AUTOSAR XML (schema 00046)
package /ComponentTypes
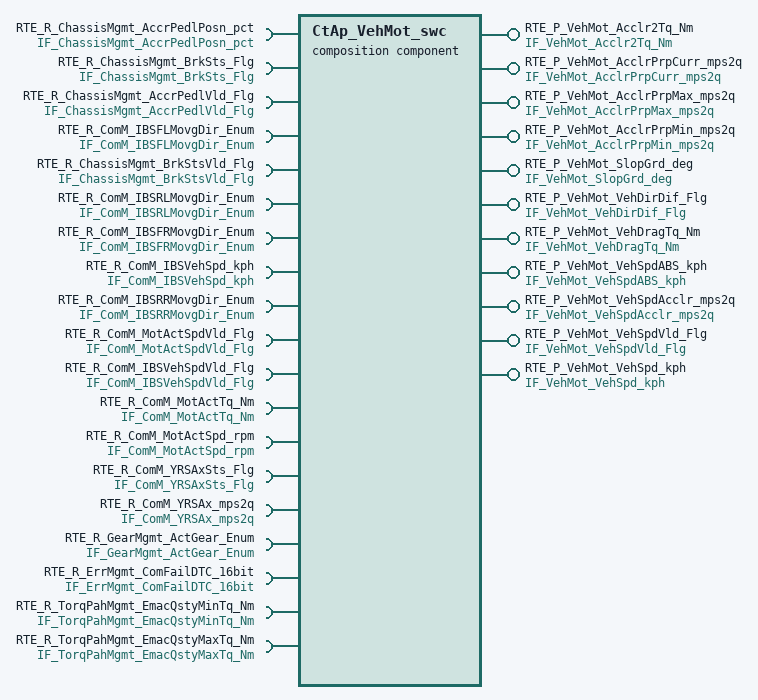
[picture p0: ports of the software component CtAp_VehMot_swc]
  composition sw component type CtAp_VehMot_swc
    11 x provide port:
      RTE_P_VehMot_Acclr2Tq_Nm: nonqueued-sender-com-spec{data-element=tec_VehMot_Acclr2Tq_Nm, init-value=0}, provided-interface=IF_VehMot_Acclr2Tq_Nm
      RTE_P_VehMot_AcclrPrpCurr_mps2q: nonqueued-sender-com-spec{data-element=tec_VehMot_AcclrPrpCurr_mps2q, init-value=0}, provided-interface=IF_VehMot_AcclrPrpCurr_mps2q
      RTE_P_VehMot_AcclrPrpMax_mps2q: nonqueued-sender-com-spec{data-element=tec_VehMot_AcclrPrpMax_mps2q, init-value=0}, provided-interface=IF_VehMot_AcclrPrpMax_mps2q
      RTE_P_VehMot_AcclrPrpMin_mps2q: nonqueued-sender-com-spec{data-element=tec_VehMot_AcclrPrpMin_mps2q, init-value=0}, provided-interface=IF_VehMot_AcclrPrpMin_mps2q
      RTE_P_VehMot_SlopGrd_deg: nonqueued-sender-com-spec{data-element=tec_VehMot_SlopGrd_deg, init-value=0}, provided-interface=IF_VehMot_SlopGrd_deg
      RTE_P_VehMot_VehDirDif_Flg: nonqueued-sender-com-spec{data-element=tec_VehMot_VehDirDif_Flg, init-value=0}, provided-interface=IF_VehMot_VehDirDif_Flg
      RTE_P_VehMot_VehDragTq_Nm: nonqueued-sender-com-spec{data-element=tec_VehMot_VehDragTq_Nm, init-value=0}, provided-interface=IF_VehMot_VehDragTq_Nm
      RTE_P_VehMot_VehSpdABS_kph: nonqueued-sender-com-spec{data-element=tec_VehMot_VehSpdABS_kph, init-value=0}, provided-interface=IF_VehMot_VehSpdABS_kph
      RTE_P_VehMot_VehSpdAcclr_mps2q: nonqueued-sender-com-spec{data-element=tec_VehMot_VehSpdAcclr_mps2q, init-value=0}, provided-interface=IF_VehMot_VehSpdAcclr_mps2q
      RTE_P_VehMot_VehSpdVld_Flg: nonqueued-sender-com-spec{data-element=tec_VehMot_VehSpdVld_Flg, init-value=0}, provided-interface=IF_VehMot_VehSpdVld_Flg
      RTE_P_VehMot_VehSpd_kph: nonqueued-sender-com-spec{data-element=tec_VehMot_VehSpd_kph, init-value=0}, provided-interface=IF_VehMot_VehSpd_kph
    19 x require port:
      RTE_R_ChassisMgmt_AccrPedlPosn_pct: nonqueued-receiver-com-spec{data-element=tec_ChassisMgmt_AccrPedlPosn_pct, filter=data-filter-type=ALWAYS, init-value=0}, required-interface=IF_ChassisMgmt_AccrPedlPosn_pct
      RTE_R_ChassisMgmt_BrkSts_Flg: nonqueued-receiver-com-spec{data-element=tec_ChassisMgmt_BrkSts_Flg, filter=data-filter-type=ALWAYS, init-value=0}, required-interface=IF_ChassisMgmt_BrkSts_Flg
      RTE_R_ChassisMgmt_AccrPedlVld_Flg: nonqueued-receiver-com-spec{data-element=tec_ChassisMgmt_AccrPedlVld_Flg, filter=data-filter-type=ALWAYS, init-value=0}, required-interface=IF_ChassisMgmt_AccrPedlVld_Flg
      RTE_R_ComM_IBSFLMovgDir_Enum: nonqueued-receiver-com-spec{data-element=tec_ComM_IBSFLMovgDir_Enum, filter=data-filter-type=ALWAYS, init-value=0}, required-interface=IF_ComM_IBSFLMovgDir_Enum
      RTE_R_ChassisMgmt_BrkStsVld_Flg: nonqueued-receiver-com-spec{data-element=tec_ChassisMgmt_BrkStsVld_Flg, filter=data-filter-type=ALWAYS, init-value=0}, required-interface=IF_ChassisMgmt_BrkStsVld_Flg
      RTE_R_ComM_IBSRLMovgDir_Enum: nonqueued-receiver-com-spec{data-element=tec_ComM_IBSRLMovgDir_Enum, filter=data-filter-type=ALWAYS, init-value=0}, required-interface=IF_ComM_IBSRLMovgDir_Enum
      RTE_R_ComM_IBSFRMovgDir_Enum: nonqueued-receiver-com-spec{data-element=tec_ComM_IBSFRMovgDir_Enum, filter=data-filter-type=ALWAYS, init-value=0}, required-interface=IF_ComM_IBSFRMovgDir_Enum
      RTE_R_ComM_IBSVehSpd_kph: nonqueued-receiver-com-spec{data-element=tec_ComM_IBSVehSpd_kph, filter=data-filter-type=ALWAYS, init-value=0}, required-interface=IF_ComM_IBSVehSpd_kph
      RTE_R_ComM_IBSRRMovgDir_Enum: nonqueued-receiver-com-spec{data-element=tec_ComM_IBSRRMovgDir_Enum, filter=data-filter-type=ALWAYS, init-value=0}, required-interface=IF_ComM_IBSRRMovgDir_Enum
      RTE_R_ComM_MotActSpdVld_Flg: nonqueued-receiver-com-spec{data-element=tec_ComM_MotActSpdVld_Flg, filter=data-filter-type=ALWAYS, init-value=0}, required-interface=IF_ComM_MotActSpdVld_Flg
      RTE_R_ComM_IBSVehSpdVld_Flg: nonqueued-receiver-com-spec{data-element=tec_ComM_IBSVehSpdVld_Flg, filter=data-filter-type=ALWAYS, init-value=0}, required-interface=IF_ComM_IBSVehSpdVld_Flg
      RTE_R_ComM_MotActTq_Nm: nonqueued-receiver-com-spec{data-element=tec_ComM_MotActTq_Nm, filter=data-filter-type=ALWAYS, init-value=0}, required-interface=IF_ComM_MotActTq_Nm
      RTE_R_ComM_MotActSpd_rpm: nonqueued-receiver-com-spec{data-element=tec_ComM_MotActSpd_rpm, filter=data-filter-type=ALWAYS, init-value=0}, required-interface=IF_ComM_MotActSpd_rpm
      RTE_R_ComM_YRSAxSts_Flg: nonqueued-receiver-com-spec{data-element=tec_ComM_YRSAxSts_Flg, filter=data-filter-type=ALWAYS, init-value=0}, required-interface=IF_ComM_YRSAxSts_Flg
      RTE_R_ComM_YRSAx_mps2q: nonqueued-receiver-com-spec{data-element=tec_ComM_YRSAx_mps2q, filter=data-filter-type=ALWAYS, init-value=0}, required-interface=IF_ComM_YRSAx_mps2q
      RTE_R_GearMgmt_ActGear_Enum: nonqueued-receiver-com-spec{data-element=tec_GearMgmt_ActGear_Enum, filter=data-filter-type=ALWAYS, init-value=0}, required-interface=IF_GearMgmt_ActGear_Enum
      RTE_R_ErrMgmt_ComFailDTC_16bit: nonqueued-receiver-com-spec{data-element=tec_ErrMgmt_ComFailDTC_16bit, filter=data-filter-type=ALWAYS, init-value=0}, required-interface=IF_ErrMgmt_ComFailDTC_16bit
      RTE_R_TorqPahMgmt_EmacQstyMinTq_Nm: nonqueued-receiver-com-spec{data-element=tec_TorqPahMgmt_EmacQstyMinTq_Nm, filter=data-filter-type=ALWAYS, init-value=0}, required-interface=IF_TorqPahMgmt_EmacQstyMinTq_Nm
      RTE_R_TorqPahMgmt_EmacQstyMaxTq_Nm: nonqueued-receiver-com-spec{data-element=tec_TorqPahMgmt_EmacQstyMaxTq_Nm, filter=data-filter-type=ALWAYS, init-value=0}, required-interface=IF_TorqPahMgmt_EmacQstyMaxTq_Nm
    4 x component:
      CtAp_VehSpd: type=CtAp_VehSpd
      CtAp_AccCal: type=CtAp_AccCal
      CtAp_SlopEst: type=CtAp_SlopEst
      CtAp_ResEst: type=CtAp_ResEst
    connect CtAp_VehSpd.RTE_P_VehMot_VehSpd_kph -> CtAp_ResEst.RTE_R_VehMot_VehSpd_kph
    connect CtAp_AccCal.RTE_P_VehMot_VehSpdAcclr_mps2q -> CtAp_ResEst.RTE_R_VehMot_VehSpdAcclr_mps2q
    connect CtAp_VehSpd.RTE_P_VehMot_VehSpdVld_Flg -> CtAp_ResEst.RTE_R_VehMot_VehSpdVld_Flg
    connect CtAp_VehSpd.RTE_P_VehMot_VehSpd_kph -> CtAp_SlopEst.RTE_R_VehMot_VehSpd_kph
    connect CtAp_AccCal.RTE_P_VehMot_VehSpdAcclr_mps2q -> CtAp_SlopEst.RTE_R_VehMot_VehSpdAcclr_mps2q
    delegate CtAp_ResEst.RTE_P_VehMot_Acclr2Tq_Nm <-> outer port RTE_P_VehMot_Acclr2Tq_Nm
    delegate CtAp_ResEst.RTE_P_VehMot_AcclrPrpCurr_mps2q <-> outer port RTE_P_VehMot_AcclrPrpCurr_mps2q
    delegate CtAp_ResEst.RTE_P_VehMot_AcclrPrpMax_mps2q <-> outer port RTE_P_VehMot_AcclrPrpMax_mps2q
    delegate CtAp_ResEst.RTE_P_VehMot_AcclrPrpMin_mps2q <-> outer port RTE_P_VehMot_AcclrPrpMin_mps2q
    delegate CtAp_SlopEst.RTE_P_VehMot_SlopGrd_deg <-> outer port RTE_P_VehMot_SlopGrd_deg
    delegate CtAp_VehSpd.RTE_P_VehMot_VehDirDif_Flg <-> outer port RTE_P_VehMot_VehDirDif_Flg
    delegate CtAp_ResEst.RTE_P_VehMot_VehDragTq_Nm <-> outer port RTE_P_VehMot_VehDragTq_Nm
    delegate CtAp_VehSpd.RTE_P_VehMot_VehSpd_kph <-> outer port RTE_P_VehMot_VehSpd_kph
    delegate CtAp_VehSpd.RTE_P_VehMot_VehSpdABS_kph <-> outer port RTE_P_VehMot_VehSpdABS_kph
    delegate CtAp_AccCal.RTE_P_VehMot_VehSpdAcclr_mps2q <-> outer port RTE_P_VehMot_VehSpdAcclr_mps2q
    delegate CtAp_VehSpd.RTE_P_VehMot_VehSpdVld_Flg <-> outer port RTE_P_VehMot_VehSpdVld_Flg
    delegate CtAp_AccCal.RTE_R_ComM_YRSAx_mps2q <-> outer port RTE_R_ComM_YRSAx_mps2q
    delegate CtAp_AccCal.RTE_R_ComM_YRSAxSts_Flg <-> outer port RTE_R_ComM_YRSAxSts_Flg
    connect CtAp_VehSpd.RTE_P_VehMot_VehSpd_kph -> CtAp_AccCal.RTE_R_VehMot_VehSpd_kph
    delegate CtAp_ResEst.RTE_R_ChassisMgmt_BrkSts_Flg <-> outer port RTE_R_ChassisMgmt_BrkSts_Flg
    delegate CtAp_ResEst.RTE_R_ChassisMgmt_BrkStsVld_Flg <-> outer port RTE_R_ChassisMgmt_BrkStsVld_Flg
    delegate CtAp_ResEst.RTE_R_ComM_MotActTq_Nm <-> outer port RTE_R_ComM_MotActTq_Nm
    delegate CtAp_ResEst.RTE_R_ComM_YRSAx_mps2q <-> outer port RTE_R_ComM_YRSAx_mps2q
    delegate CtAp_ResEst.RTE_R_ComM_YRSAxSts_Flg <-> outer port RTE_R_ComM_YRSAxSts_Flg
    delegate CtAp_ResEst.RTE_R_TorqPahMgmt_EmacQstyMaxTq_Nm <-> outer port RTE_R_TorqPahMgmt_EmacQstyMaxTq_Nm
    delegate CtAp_ResEst.RTE_R_TorqPahMgmt_EmacQstyMinTq_Nm <-> outer port RTE_R_TorqPahMgmt_EmacQstyMinTq_Nm
    delegate CtAp_SlopEst.RTE_R_ChassisMgmt_AccrPedlPosn_pct <-> outer port RTE_R_ChassisMgmt_AccrPedlPosn_pct
    delegate CtAp_SlopEst.RTE_R_ChassisMgmt_AccrPedlVld_Flg <-> outer port RTE_R_ChassisMgmt_AccrPedlVld_Flg
    delegate CtAp_SlopEst.RTE_R_ChassisMgmt_BrkSts_Flg <-> outer port RTE_R_ChassisMgmt_BrkSts_Flg
    delegate CtAp_SlopEst.RTE_R_ChassisMgmt_BrkStsVld_Flg <-> outer port RTE_R_ChassisMgmt_BrkStsVld_Flg
    delegate CtAp_SlopEst.RTE_R_ComM_YRSAx_mps2q <-> outer port RTE_R_ComM_YRSAx_mps2q
    delegate CtAp_SlopEst.RTE_R_ComM_YRSAxSts_Flg <-> outer port RTE_R_ComM_YRSAxSts_Flg
    delegate CtAp_VehSpd.RTE_R_ComM_IBSFLMovgDir_Enum <-> outer port RTE_R_ComM_IBSFLMovgDir_Enum
    delegate CtAp_VehSpd.RTE_R_ComM_IBSFRMovgDir_Enum <-> outer port RTE_R_ComM_IBSFRMovgDir_Enum
    delegate CtAp_VehSpd.RTE_R_ComM_IBSRLMovgDir_Enum <-> outer port RTE_R_ComM_IBSRLMovgDir_Enum
    delegate CtAp_VehSpd.RTE_R_ComM_IBSRRMovgDir_Enum <-> outer port RTE_R_ComM_IBSRRMovgDir_Enum
    delegate CtAp_VehSpd.RTE_R_ComM_IBSVehSpd_kph <-> outer port RTE_R_ComM_IBSVehSpd_kph
    delegate CtAp_VehSpd.RTE_R_ComM_IBSVehSpdVld_Flg <-> outer port RTE_R_ComM_IBSVehSpdVld_Flg
    delegate CtAp_VehSpd.RTE_R_ComM_MotActSpd_rpm <-> outer port RTE_R_ComM_MotActSpd_rpm
    delegate CtAp_VehSpd.RTE_R_ComM_MotActSpdVld_Flg <-> outer port RTE_R_ComM_MotActSpdVld_Flg
    delegate CtAp_VehSpd.RTE_R_ErrMgmt_ComFailDTC_16bit <-> outer port RTE_R_ErrMgmt_ComFailDTC_16bit
    delegate CtAp_VehSpd.RTE_R_GearMgmt_ActGear_Enum <-> outer port RTE_R_GearMgmt_ActGear_Enum
